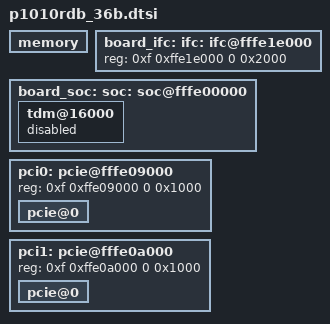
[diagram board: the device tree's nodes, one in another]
/*
 * P1010 RDB Device Tree Source Stub
 *
 * Copyright 2013 Freescale Semiconductor Inc.
 *
 * This program is free software; you can redistribute  it and/or modify it
 * under  the terms of  the GNU General  Public License as published by the
 * Free Software Foundation;  either version 2 of the  License, or (at your
 * option) any later version.
 */

memory {
	device_type = "memory";
};

board_ifc: ifc: ifc@fffe1e000 {
	/* NOR, NAND Flashes and CPLD on board */
	ranges = <0x0 0x0 0xf 0xee000000 0x02000000
		  0x1 0x0 0xf 0xff800000 0x00010000
		  0x3 0x0 0xf 0xffb00000 0x00000020>;
	reg = <0xf 0xffe1e000 0 0x2000>;
};

board_soc: soc: soc@fffe00000 {
	ranges = <0x0 0xf 0xffe00000 0x100000>;
	tdm@16000 {
		status = "disabled";
	};
};

pci0: pcie@fffe09000 {
	reg = <0xf 0xffe09000 0 0x1000>;
	ranges = <0x2000000 0x0 0xc0000000 0xc 0x20000000 0x0 0x20000000
		  0x1000000 0x0 0x00000000 0xf 0xffc10000 0x0 0x10000>;
	pcie@0 {
		ranges = <0x2000000 0x0 0xc0000000
			  0x2000000 0x0 0xc0000000
			  0x0 0x20000000

			  0x1000000 0x0 0x0
			  0x1000000 0x0 0x0
			  0x0 0x100000>;
	};
};

pci1: pcie@fffe0a000 {
	reg = <0xf 0xffe0a000 0 0x1000>;
	ranges = <0x2000000 0x0 0xc0000000 0xc 0x20000000 0x0 0x20000000
		  0x1000000 0x0 0x00000000 0xf 0xffc10000 0x0 0x10000>;
	pcie@0 {
		ranges = <0x2000000 0x0 0xc0000000
			  0x2000000 0x0 0xc0000000
			  0x0 0x20000000

			  0x1000000 0x0 0x0
			  0x1000000 0x0 0x0
			  0x0 0x100000>;
	};
};
